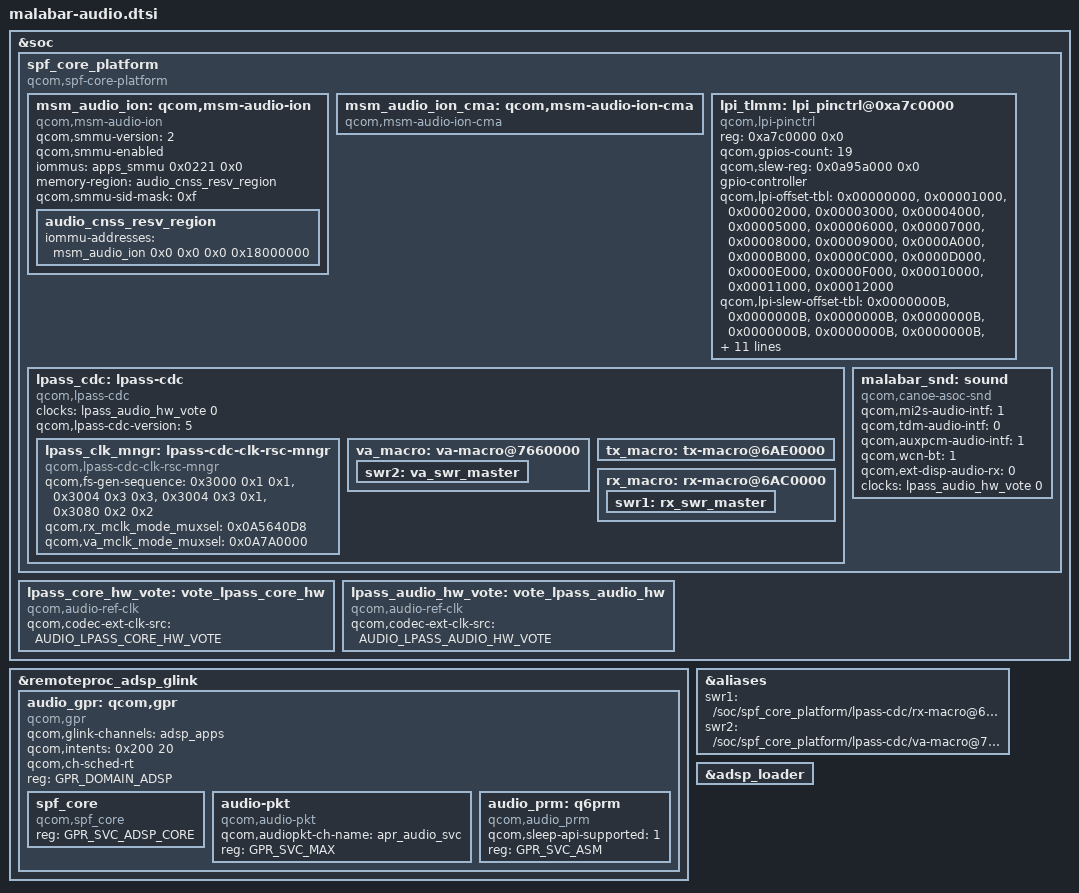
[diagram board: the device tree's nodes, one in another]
//
/* Copyright (c) Qualcomm Technologies, Inc. and/or its subsidiaries.
 * SPDX-License-Identifier: BSD-3-Clause
 */

#include <bindings/qcom,audio-ext-clk.h>
#include <bindings/qcom,gpr.h>
#include "msm-audio-lpass.dtsi"
&soc {
	spf_core_platform: spf_core_platform {
		compatible = "qcom,spf-core-platform";
	};

	lpass_core_hw_vote: vote_lpass_core_hw {
		compatible = "qcom,audio-ref-clk";
		qcom,codec-ext-clk-src = <AUDIO_LPASS_CORE_HW_VOTE>;
		#clock-cells = <1>;
	};

	lpass_audio_hw_vote: vote_lpass_audio_hw {
		compatible = "qcom,audio-ref-clk";
		qcom,codec-ext-clk-src = <AUDIO_LPASS_AUDIO_HW_VOTE>;
		#clock-cells = <1>;
	};
};

&remoteproc_adsp_glink {
	audio_gpr: qcom,gpr {
		compatible = "qcom,gpr";
		qcom,glink-channels = "adsp_apps";
		qcom,intents = <0x200 20>;
		qcom,ch-sched-rt;
		reg = <GPR_DOMAIN_ADSP>;

		spf_core {
			compatible = "qcom,spf_core";
			reg = <GPR_SVC_ADSP_CORE>;
		};

		audio-pkt {
			compatible = "qcom,audio-pkt";
			qcom,audiopkt-ch-name = "apr_audio_svc";
			reg = <GPR_SVC_MAX>;
		};

		audio_prm: q6prm {
			compatible = "qcom,audio_prm";
			qcom,sleep-api-supported = <1>;
			reg = <GPR_SVC_ASM>;
		};
	};
};

&spf_core_platform {
	#address-cells = <2>;
	#size-cells = <2>;
	msm_audio_ion: qcom,msm-audio-ion {
		compatible = "qcom,msm-audio-ion";
		qcom,smmu-version = <2>;
		qcom,smmu-enabled;
		iommus = <&apps_smmu 0x0221 0x0>;
		memory-region = <&audio_cnss_resv_region>;
		qcom,smmu-sid-mask = /bits/ 64 <0xf>;

		audio_cnss_resv_region: audio_cnss_resv_region {
			iommu-addresses = <&msm_audio_ion 0x0 0x0 0x0 0x18000000>;
		};
	};

	msm_audio_ion_cma: qcom,msm-audio-ion-cma {
		compatible = "qcom,msm-audio-ion-cma";
	};

	lpi_tlmm: lpi_pinctrl@0xa7c0000 {
		compatible = "qcom,lpi-pinctrl";
		reg = <0xa7c0000 0x0>;
		qcom,gpios-count = <19>;
		qcom,slew-reg = <0x0a95a000 0x0>;
		gpio-controller;
		#gpio-cells = <2>;
		qcom,lpi-offset-tbl = <0x00000000>, <0x00001000>,
					<0x00002000>, <0x00003000>,
					<0x00004000>, <0x00005000>,
					<0x00006000>, <0x00007000>,
					<0x00008000>, <0x00009000>,
					<0x0000A000>, <0x0000B000>,
					<0x0000C000>, <0x0000D000>,
					<0x0000E000>, <0x0000F000>,
					<0x00010000>, <0x00011000>,
					<0x00012000>;
		qcom,lpi-slew-offset-tbl = <0x0000000B>, <0x0000000B>,
						<0x0000000B>, <0x0000000B>,
						<0x0000000B>, <0x0000000B>,
						<0x0000000B>, <0x0000000B>,
						<0x0000000B>, <0x0000000B>,
						<0x0000000B>, <0x0000000B>,
						<0x0000000B>, <0x0000000B>,
						<0x0000000B>, <0x0000000B>,
						<0x0000000B>, <0x0000000B>,
						<0x0000000B>;

		qcom,lpi-slew-base-tbl = <0xA7C0000>, <0xA7C1000>,
						<0xA7C2000>, <0xA7C3000>,
						<0xA7C4000>, <0xA7C5000>,
						<0xA7C6000>, <0xA7C7000>,
						<0xA7C8000>, <0xA7C9000>,
						<0xA7CA000>, <0xA7CB000>,
						<0xA7CC000>, <0xA7CD000>,
						<0xA7CE000>, <0xA7CF000>,
						<0xA7D0000>, <0xA7D1000>,
						<0xA7D2000>;

		clock-names = "lpass_audio_hw_vote";
		clocks = <&lpass_audio_hw_vote 0>;
	};

	lpass_cdc: lpass-cdc {
		compatible = "qcom,lpass-cdc";
		clock-names = "lpass_audio_hw_vote";
		clocks = <&lpass_audio_hw_vote 0>;
		qcom,lpass-cdc-version = <5>;
		lpass_clk_mngr: lpass-cdc-clk-rsc-mngr {
			compatible = "qcom,lpass-cdc-clk-rsc-mngr";
			qcom,fs-gen-sequence = <0x3000 0x1 0x1>, <0x3004 0x3 0x3>,
					<0x3004 0x3 0x1>, <0x3080 0x2 0x2>;
			qcom,rx_mclk_mode_muxsel = <0x0A5640D8>;
			qcom,va_mclk_mode_muxsel = <0x0A7A0000>;
		};

		va_macro: va-macro@7660000 {
			swr2: va_swr_master {
			};
		};

		tx_macro: tx-macro@6AE0000 {
		};

		rx_macro: rx-macro@6AC0000 {
			swr1: rx_swr_master {
			};
		};

	};

	malabar_snd: sound {
		compatible = "qcom,canoe-asoc-snd";
		qcom,mi2s-audio-intf = <1>;
		qcom,tdm-audio-intf = <0>;
		qcom,auxpcm-audio-intf = <1>;
		qcom,wcn-bt = <1>;
		qcom,ext-disp-audio-rx = <0>;
		clock-names = "lpass_audio_hw_vote";
		clocks = <&lpass_audio_hw_vote 0>;
	};
};

&aliases {
	swr1 = "/soc/spf_core_platform/lpass-cdc/rx-macro@6AC0000/rx_swr_master";
	swr2 = "/soc/spf_core_platform/lpass-cdc/va-macro@7660000/va_swr_master";
};

&adsp_loader {
	/delete-property/ qcom,adsp-state;
};
